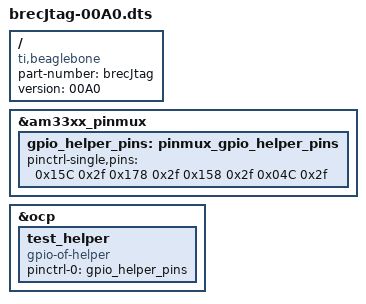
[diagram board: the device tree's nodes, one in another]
/dts-v1/;
/plugin/;

/ {
	compatible = "ti,beaglebone", "ti,beaglebone-black";

	/* identification */
	part-number = "brecJtag";
	version     = "00A0";

        /*--------------------------------------------------------------------*/
	fragment@0 {
		target = <&am33xx_pinmux>;
		__overlay__ {
                       gpio_helper_pins: pinmux_gpio_helper_pins {
                                pinctrl-single,pins = <
        /* See pad control registers section spruh73h p747 */
        0x15C 0x2f      /* P9.17 GPIO0_5   MODE7 | IO  */
        0x178 0x2f      /* P9.20 GPIO0_12  MODE7 | IO  */
        0x158 0x2f      /* P9.18 GPIO0_4   MODE7 | IO   */
        0x04C 0x2f      /* P9.16 GPIO1_19  MODE7 | IO  */
                                >;
                        };
		}; // End of pinumx
	}; // End of fragment 0

        fragment@1 {
            target = <&ocp>;
            __overlay__ {
               test_helper {
                   compatible    = "gpio-of-helper";
                   pinctrl-names = "default";
                   pinctrl-0     = <&gpio_helper_pins>;
                   status        = "okay";
               };
            };
        };

};
